# pse84_a0 register map
Vendor: Infineon Technologies; Series: PSE84_A0; File version: 1.0
CPU: CM33 r0p1, little endian, MPU, FPU, VTOR, 3 interrupt priority bits
Registers are 32-bit, read-write, reset 0x0 unless marked. A register's access mark holds for its fields unless they carry their own. Offsets are from the block's base; [hi:lo] are bit positions.

## MXNNLITE_1_0
Base 0x42D80000
0x04 WEIGHTSTREAMERBASEADDR
  [31:0] WEIGHTSTREAMERBASEADDR — Byte addresses, defines the address of the first dataset (first row, first col) programmable:configurable only when IP is enabled by SL_CTL bit. Do not update while a layer computation is active (BUSY_STATUS='1')! Updating during BUSY_STATUS='1' will cause unpredictable behavior.
0x08 WEIGHTSTREAMEROFFSET
  [8:0] WEIGHTSTREAMEROFFSET — Signed offset added to every weight programmable:configurable only when IP is enabled by SL_CTL bit. Do not update while a layer computation is active (BUSY_STATUS='1')! Updating during BUSY_STATUS='1' will cause unpredictable behavior.
0x0C WEIGHTSTREAMERKERNELCHANNELTIMESHEIGHTTIMESWIDTH
  [17:0] WEIGHTSTREAMERKERNELCHANNELTIMESHEIGHTTIMESWIDTH — Unsigned total number of kernel elements, disables Streamer, when last element reached. FSM updates this register as the number of nonzeroweights when sparsity is enabled, data is valid from bias streamer programmable:configurable only when IP is enabled by SL_CTL bit. Do not update while a layer computation is active (BUSY_STATUS='1')! Updating during BUSY_STATUS='1' will cause unpredictable behavior.
0x10 ACTIVATIONSTREAMERBASEADDR
  [31:0] ACTIVATIONSTREAMERBASEADDR — Byte addresses, defines the address of the first dataset (first row, first col) programmable:configurable only when IP is enabled by SL_CTL bit. Do not update while a layer computation is active (BUSY_STATUS='1')! Updating during BUSY_STATUS='1' will cause unpredictable behavior.
0x14 ACTIVATIONSTREAMEROFFSET
  [16:0] ACTIVATIONSTREAMEROFFSET — 9-bit or 17-bit signed offset added to fetch data programmable:configurable only when IP is enabled by SL_CTL bit. Do not update while a layer computation is active (BUSY_STATUS='1')! Updating during BUSY_STATUS='1' will cause unpredictable behavior.
0x18 ACTIVATIONSTREAMERKERNELCHANNELTIMESWIDTH
  [17:0] ACTIVATIONSTREAMERKERNELCHANNELTIMESWIDTH — Kernel channel times width (input assumed to be 2D row-minor or row/channel minor memory layout) programmable:configurable only when IP is enabled by SL_CTL bit. Do not update while a layer computation is active (BUSY_STATUS='1')! Updating during BUSY_STATUS='1' will cause unpredictable behavior.
0x1C ACTIVATIONSTREAMERKERNELHEIGHT
  [16:0] ACTIVATIONSTREAMERKERNELHEIGHT — Kernel height (input assumed to be 2D row-minor or row/channel minor memory layout) programmable:configurable only when IP is enabled by SL_CTL bit. Do not update while a layer computation is active (BUSY_STATUS='1')! Updating during BUSY_STATUS='1' will cause unpredictable behavior.
0x20 ACTIVATIONSTREAMERREPEATS
  [17:0] ACTIVATIONSTREAMERREPEATS — Numer of repeated fetches of kernel footprint in memory ( 1 will fetch once, 0 is invalid input) programmable:configurable only when IP is enabled by SL_CTL bit. Do not update while a layer computation is active (BUSY_STATUS='1')! Updating during BUSY_STATUS='1' will cause unpredictable behavior.
0x24 ACTIVATIONSTREAMERSTARTCOL
  [17:0] ACTIVATIONSTREAMERSTARTCOL — Signed start column to move kernel window over the activation map (col=0 & row=0 hits baseaddr) programmable:configurable only when IP is enabled by SL_CTL bit. Do not update while a layer computation is active (BUSY_STATUS='1')! Updating during BUSY_STATUS='1' will cause unpredictable behavior.
0x28 ACTIVATIONSTREAMERSTARTROW
  [17:0] ACTIVATIONSTREAMERSTARTROW — Signed start row to move kernel window over the activation map (col=0 & row=0 hits baseaddr) programmable:configurable only when IP is enabled by SL_CTL bit. Do not update while a layer computation is active (BUSY_STATUS='1')! Updating during BUSY_STATUS='1' will cause unpredictable behavior.
0x2C ACTIVATIONSTREAMERCHANNELTIMESWIDTH
  [16:0] ACTIVATIONSTREAMERCHANNELTIMESWIDTH — Unsigned number of elements in activation map per channel * width programmable:configurable only when IP is enabled by SL_CTL bit. Do not update while a layer computation is active (BUSY_STATUS='1')! Updating during BUSY_STATUS='1' will cause unpredictable behavior.
0x30 ACTIVATIONSTREAMERHEIGHT
  [16:0] ACTIVATIONSTREAMERHEIGHT — Unsigned number of elements in height in activation map till end of loop programmable:configurable only when IP is enabled by SL_CTL bit. Do not update while a layer computation is active (BUSY_STATUS='1')! Updating during BUSY_STATUS='1' will cause unpredictable behavior.
0x34 ACTIVATIONSTREAMERPADDING
  [15:0] ACTIVATIONSTREAMERPADVALUE — Defines unsigned values out of activation map programmable:configurable only when IP is enabled by SL_CTL bit. Do not update while a layer computation is active (BUSY_STATUS='1')! Updating during BUSY_STATUS='1' will cause unpredictable behavior.
0x38 ACTIVATIONSTREAMERSPARSITYMAPBASEADDR
  [31:0] ACTIVATIONSTREAMERSPARSITYMAPBASEADDR — Byte addresses, defines the address of start of sparsity bit(map) for sparse footprint fetch programmable:configurable only when IP is enabled by SL_CTL bit. Do not update while a layer computation is active (BUSY_STATUS='1')! Updating during BUSY_STATUS='1' will cause unpredictable behavior.
0x3C OUTSTREAMERBASEADDR
  [31:0] OUTSTREAMERBASEADDR — Byte addresses, defines the address of the first dataset (first row, first col) programmable:configurable only when IP is enabled by SL_CTL bit. Do not update while a layer computation is active (BUSY_STATUS='1')! Updating during BUSY_STATUS='1' will cause unpredictable behavior.
0x40 OUTSTREAMEROUTPUTOFFSET
  [16:0] OUTSTREAMEROUTPUTOFFSET — Signed offset added to the output activation. The outstreamer supports 8-bit output neuron. The configuration range is [-256, 255] programmable:configurable only when IP is enabled by SL_CTL bit. Do not update while a layer computation is active (BUSY_STATUS='1')! Updating during BUSY_STATUS='1' will cause unpredictable behavior.
0x44 OUTSTREAMERSCALINGFACTOR
  [31:0] OUTSTREAMERSCALINGFACTOR — Scales the output activation with this floating point value [Default is set to 0x3f800000 -> 1.0] programmable:configurable only when IP is enabled by SL_CTL bit. Do not update while a layer computation is active (BUSY_STATUS='1')! Updating during BUSY_STATUS='1' will cause unpredictable behavior.
0x48 OUTSTREAMERCLIPPINGMASK
  [31:0] OUTSTREAMERCLIPPINGMASK — Values that are taking more than the defined bits get saturated to the max/min(signed) represented value, eg. Use 0x000000ff for byte clipping [Default is 0xffffffff-> no clipping] programmable:configurable only when IP is enabled by SL_CTL bit. Do not update while a layer computation is active (BUSY_STATUS='1')! Updating during BUSY_STATUS='1' will cause unpredictable behavior.
0x4C BIASBASEADDR
  [31:0] BIASBASEADDR — Word aligned addresses, defines the address of the bias. Bias is 32 bits. programmable:configurable only when IP is enabled by SL_CTL bit. Do not update while a layer computation is active (BUSY_STATUS='1')! Updating during BUSY_STATUS='1' will cause unpredictable behavior.
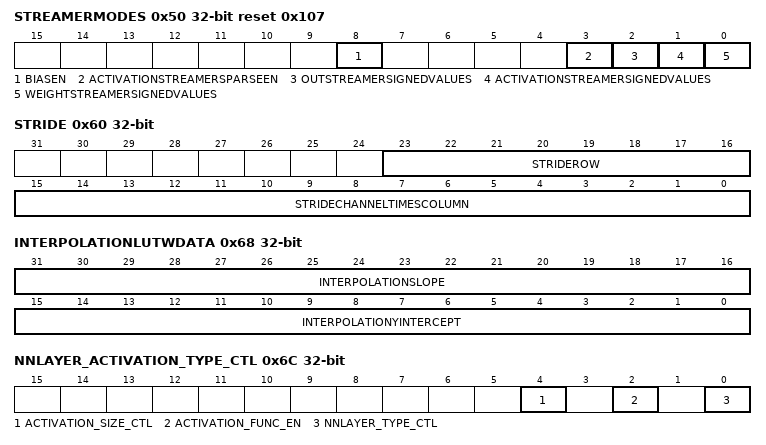
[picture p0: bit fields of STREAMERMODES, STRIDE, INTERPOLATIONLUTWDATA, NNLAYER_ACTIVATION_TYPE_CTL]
0x50 STREAMERMODES reset 0x107
  [8] BIASEN — Enable bias when bias exists for the kernels or weigths programmable:configurable only when IP is enabled by SL_CTL bit. Do not update while a layer computation is active (BUSY_STATUS='1')! Updating during BUSY_STATUS='1' will cause unpredictable behavior.
  [3] ACTIVATIONSTREAMERSPARSEEN — Enable sparse footprint fetch - fetch only footprint values for which corresponding sparsity bitmap bit is set (left-to-right, top-bottom order). programmable:configurable only when IP is enabled by SL_CTL bit. Do not update while a layer computation is active (BUSY_STATUS='1')! Updating during BUSY_STATUS='1' will cause unpredictable behavior.
  [2] OUTSTREAMERSIGNEDVALUES ro — Treating signed or unsigned output activation, needed for proper Scaling and Clipping and Activation function control.
  [1] ACTIVATIONSTREAMERSIGNEDVALUES ro — Fetched/Padding values are signed-extended before offset addition
  [0] WEIGHTSTREAMERSIGNEDVALUES ro — Fetched/Padding values are signed-extended before offset addition
0x54 NONZEROWEIGHTSPOINTER — Memory address, which stores the number of the non-zero weights
  [31:0] NONZEROWEIGHTSPOINTER — Memory address, which stores the number of the non-zero weights. It is half-word aligned. The non-zero weights size is 16 bits. programmable:configurable only when IP is enabled by SL_CTL bit. Do not update while a layer computation is active (BUSY_STATUS='1')! Updating during BUSY_STATUS='1' will cause unpredictable behavior.
0x58 OUTPUTWIDTH — Output width for one layer
  [16:0] OUTPUTWIDTH — Output width for one layer programmable:configurable only when IP is enabled by SL_CTL bit. Do not update while a layer computation is active (BUSY_STATUS='1')! Updating during BUSY_STATUS='1' will cause unpredictable behavior.
0x5C OUTPUTHEIGHT — Output height for one layer
  [16:0] OUTPUTHEIGHT — Output height for one layer programmable:configurable only when IP is enabled by SL_CTL bit. Do not update while a layer computation is active (BUSY_STATUS='1')! Updating during BUSY_STATUS='1' will cause unpredictable behavior.
0x60 STRIDE — Stride control register
  [23:16] STRIDEROW — Stride between rows. programmable:configurable only when IP is enabled by SL_CTL bit. Do not update while a layer computation is active (BUSY_STATUS='1')! Updating during BUSY_STATUS='1' will cause unpredictable behavior.
  [15:0] STRIDECHANNELTIMESCOLUMN — Stride on channel times columns. programmable:configurable only when IP is enabled by SL_CTL bit. Do not update while a layer computation is active (BUSY_STATUS='1')! Updating during BUSY_STATUS='1' will cause unpredictable behavior.
0x64 INTERPOLATIONLUTADDR
  [0] INTERPOLATIONLUTADDR — LUT entry address for Interpolation starting with 0 programmable:configurable only when IP is enabled by SL_CTL bit. Do not update while a layer computation is active (BUSY_STATUS='1')! Updating during BUSY_STATUS='1' will cause unpredictable behavior.
0x68 INTERPOLATIONLUTWDATA wo — Write data for calculation of interpolation
  [31:16] INTERPOLATIONSLOPE — Slope in floating point for calculation of interpolation. In case software reads this software write only register, the read data is 16'b0, no error response. programmable:configurable only when IP is enabled by SL_CTL bit. Do not update while a layer computation is active (BUSY_STATUS='1')! Updating during BUSY_STATUS='1' will cause unpredictable behavior.
  [15:0] INTERPOLATIONYINTERCEPT — Y-intercept in integer for calculation of interpolation. In case software reads this software write only register, the read data is 16'b0, no error response. programmable:configurable only when IP is enabled by SL_CTL bit. Do not update while a layer computation is active (BUSY_STATUS='1')! Updating during BUSY_STATUS='1' will cause unpredictable behavior.
0x6C NNLAYER_ACTIVATION_TYPE_CTL — Select layer type, activation functions and activation size
  [4] ACTIVATION_SIZE_CTL — Select activation size. Value 0: 8 bits, value 1: 16 bits programmable:configurable only when IP is enabled by SL_CTL bit. Do not update while a layer computation is active (BUSY_STATUS='1')! Updating during BUSY_STATUS='1' will cause unpredictable behavior.
  [2] ACTIVATION_FUNC_EN — Enable activation functions. Value 0: Disabled, value 1: Enabled (activation function is determined by the configured InterpolationYintercept and InterpolationSlope values) programmable:configurable only when IP is enabled by SL_CTL bit. Do not update while a layer computation is active (BUSY_STATUS='1')! Updating during BUSY_STATUS='1' will cause unpredictable behavior.
  [0] NNLAYER_TYPE_CTL — Control layer type. Value 0: Dense layer, value 1: Conv 1D layer programmable:configurable only when IP is enabled by SL_CTL bit. Do not update while a layer computation is active (BUSY_STATUS='1')! Updating during BUSY_STATUS='1' will cause unpredictable behavior.
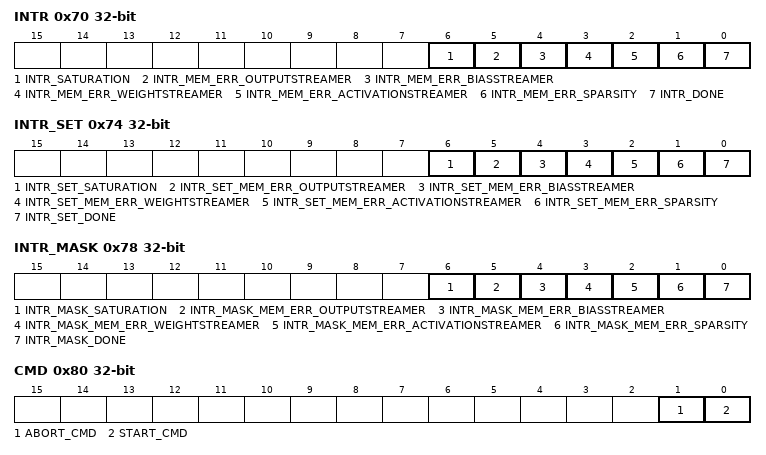
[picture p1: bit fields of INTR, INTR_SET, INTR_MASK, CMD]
0x70 INTR — Interrupt cause and clear register
  [6] INTR_SATURATION — Saturation causes interrupt
  [5] INTR_MEM_ERR_OUTPUTSTREAMER — Writing output to memory causes error
  [4] INTR_MEM_ERR_BIASSTREAMER — Accessing bias from memory causes error
  [3] INTR_MEM_ERR_WEIGHTSTREAMER — Accessing weight from memory causes error
  [2] INTR_MEM_ERR_ACTIVATIONSTREAMER — Accessing activation from memory causes error
  [1] INTR_MEM_ERR_SPARSITY — Accessing sparsity from memory causes error
  [0] INTR_DONE — Once accelerator calculation for one layer is done, interrupt is caused programmable:configurable only when IP is enabled by SL_CTL bit. Clear the interrupt cause bit. Same programmable for other bitfields
0x74 INTR_SET — Set INTR_XXX register by software for debug purpose
  [6] INTR_SET_SATURATION — Set saturation interrupt
  [5] INTR_SET_MEM_ERR_OUTPUTSTREAMER — Set writing output error
  [4] INTR_SET_MEM_ERR_BIASSTREAMER — Set accessing bias error
  [3] INTR_SET_MEM_ERR_WEIGHTSTREAMER — Set accessing weight error
  [2] INTR_SET_MEM_ERR_ACTIVATIONSTREAMER — Set accessing activation error
  [1] INTR_SET_MEM_ERR_SPARSITY — Set accessing sparsity error
  [0] INTR_SET_DONE — Set calculation done for one layer programmable:configurable only when IP is enabled by SL_CTL bit. Provides the capability to set a specific interrupt cause bit in INTR_XXX for debug purposes. Same programmable for other bitfields
0x78 INTR_MASK — Interrupt mask register. A co-located interrupt cause bit will only cause an interrupt when its mask bit is 1
  [6] INTR_MASK_SATURATION — Mask bit for saturation interrupt
  [5] INTR_MASK_MEM_ERR_OUTPUTSTREAMER — Mask bit for writing output error
  [4] INTR_MASK_MEM_ERR_BIASSTREAMER — Mask bit for accessing bias error
  [3] INTR_MASK_MEM_ERR_WEIGHTSTREAMER — Mask bit for accessing weight error
  [2] INTR_MASK_MEM_ERR_ACTIVATIONSTREAMER — Mask bit for accessing activation error
  [1] INTR_MASK_MEM_ERR_SPARSITY — Mask bit for accessing sparsity error
  [0] INTR_MASK_DONE — Mask bit for calculation done for one layer to cause interrupt programmable:configurable only when IP is enabled by SL_CTL bit. Do not update while a layer computation is active (BUSY_STATUS='1')! Updating during BUSY_STATUS='1' will cause unpredictable behavior. Same programmable for other bitfields
0x7C TRIG_MASK — Trigger mask register. Calculation done for one layer triggers DataWire when its mask bit is 1
  [0] TRIG_MASK_DONE — Mask bit for calculation done for one layer to trigger DataWire programmable:configurable only when IP is enabled by SL_CTL bit. Do not update while a layer computation is active (BUSY_STATUS='1')! Updating during BUSY_STATUS='1' will cause unpredictable behavior.
0x80 CMD — Command register
  [1] ABORT_CMD — Set abort to reset all the registers programmable:configurable only when IP is enabled by SL_CTL bit.
  [0] START_CMD — Generate start pulse for the accelerator programmable:configurable only when IP is enabled by SL_CTL bit. Do not update while a layer computation is active (BUSY_STATUS='1')! Updating during BUSY_STATUS='1' will cause unpredictable behavior.
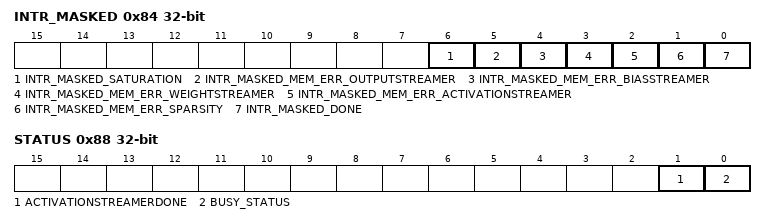
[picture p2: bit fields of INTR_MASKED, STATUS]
0x84 INTR_MASKED ro — Virtual register for generating the interrupt signal to MCU. It is the logical AND of the INTR_XXX and INTR_MASK_XXX register
  [6] INTR_MASKED_SATURATION — Masked interrupt for saturation
  [5] INTR_MASKED_MEM_ERR_OUTPUTSTREAMER — Masked interrupt for writing output error
  [4] INTR_MASKED_MEM_ERR_BIASSTREAMER — Masked interrupt for accessing bias error
  [3] INTR_MASKED_MEM_ERR_WEIGHTSTREAMER — Masked interrupt for accessing weight error
  [2] INTR_MASKED_MEM_ERR_ACTIVATIONSTREAMER — Masked interrupt for accessing activation error
  [1] INTR_MASKED_MEM_ERR_SPARSITY — Masked interrupt for accessing sparsity error
  [0] INTR_MASKED_DONE — Masked interrupt for calculation done for one layer
0x88 STATUS ro
  [1] ACTIVATIONSTREAMERDONE — Indicates when last element of repeated fetch delivered
  [0] BUSY_STATUS — Indicate IP is processing. Will be high after writing START_CMD='1' until layer computation has finished or writing ABORT_CMD='1'.
